# PIC32MK0512GPH064 device description
Architecture: MIPS; Family: PIC32MK; Series: PIC32MK
Registers are 32-bit, read-write, no defined reset value unless marked. A register's access mark holds for its fields unless they carry their own. Offsets are from the block's base; [hi:lo] are bit positions; {n}, {i} and the like mark numbered series; 'fields as' and 'values as' point back to an identical list.

## CAN
Instances: CAN 0x1f880000 in periph_pb5_std
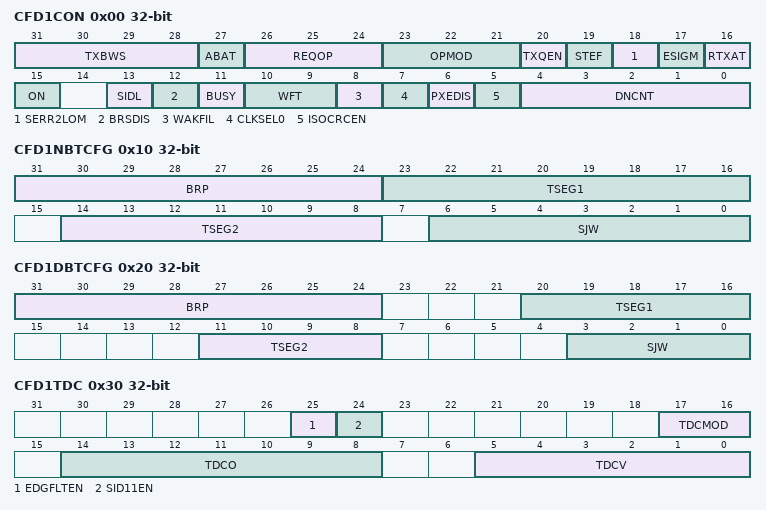
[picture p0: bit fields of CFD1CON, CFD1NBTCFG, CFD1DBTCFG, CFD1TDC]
0x00 CFD1CON — CAN Control Register
  [31:28] TXBWS — Transmit Bandwidth Sharing bits
    12=4096; 11=2048; 10=1024; 9=512; 8=256; 7=128; 6=64; 5=32; 4=16; 3=8; 2=4; 1=2; 0=No delay
  [27] ABAT — Abort All Pending Transmissions bit
    1=Signal all transmit buffers to abort transmission; 0=Module will clear this bit when all transmissions aborted
  [26:24] REQOP — Request Operation Mode bits
    7=Set Restricted Operation mode; 6=Set Normal CAN 2.0 mode; error frames on CAN FD frames; 5=Set External Loopback mode; 4=Set Configuration mode; 3=Set Listen Only mode; 2=Set Internal Loopback mode; 1=Set Disable mode; 0=Set Normal CAN FD mode; supports mixing of Full CAN FD and Classic CAN 2.0 frames
  [23:21] OPMOD — Operation Mode Status bits
    7=Module is Restricted Operation mode; 6=Module is Normal CAN 2.0 mode; error frames on CAN FD frames; 5=Module is in External Loopback mode; 4=Module is in Configuration mode; 3=Module is in Listen Only mode; 2=Module is in Internal Loopback mode; 1=Module is in Disable mode; 0=Module is in Normal CAN FD mode; supports mixing of Full CAN FD and Classic CAN 2.0 frames
  [20] TXQEN — Enable Transmit Queue bit
    1=Enables Transmit Queue and reserves space in RAM; 0=Dont reserve space in RAM for Transmit Queue
  [19] STEF — Store in Transmit Event FIFO bit
    1=Save transmitted messages in TEF; 0=Dont save transmitted messages in TEF
  [18] SERR2LOM — Transition to Listen Only Mode on System Error bit
    1=Transition to Listen Only Mode; 0=Transition to Restricted Operation Mode
  [17] ESIGM — Transmit ESI in Gateway Mode bit
    1=ESI is transmitted as recessive when ESI of message is high or CAN controller error passive; 0=ESI reflects error status of CAN controller
  [16] RTXAT — Restrict Retransmission Attempts bit
    1=Restricted retransmission attempts; 0=Unlimited number of retransmission attempts
  [15] ON — Enable bit
    1=CAN module is enabled; 0=CAN module is disabled
  [13] SIDL — Stop-in-Idle Control bit
    1=Stop module operation in Idle mode; 0=Dont stop module operation in Idle mode
  [12] BRSDIS — Bit Rate Switching Disable bit
    1=Bit Rate Switching is Disabled; 0=Bit Rate Switching depends on BRS in the Transmit Message Object
  [11] BUSY — CAN Module is Busy bit
    1=The CAN module is active; 0=The CAN module is inactive
  [10:9] WFT — Selectable Wake-up Filter Time bits
    3=T11FILTER (Typical 600 ns); 2=T10FILTER (Typical 375 ns); 1=T01FILTER (Typical 187 ns); 0=T00FILTER (Typical 100 ns)
  [8] WAKFIL — Enable CAN Bus Line Wake-up Filter bit
    1=Use CAN bus line filter for wake-up; 0=CAN bus line filter is not used for wake-up
  [7] CLKSEL0 — Module Clock Source Select bit
    1=REFCLK4 is active when the CAN FD module is enabled; 0=SYSCLK is active when the CAN FD module is enabled
  [6] PXEDIS — Protocol Exception Event Detection Disabled bit
    1=Protocol Exception is treated as a Form Error; 0=If a Protocol Exception is detected
  [5] ISOCRCEN — Enable ISO CRC in CAN FD Frames bit
    1=Include Stuff Bit Count in CRC Field and use Non-Zero CRC Initialization Vector; 0=Do not include Stuff Bit Count in CRC Field and use CRC Initialization Vector with all zeros
  [4:0] DNCNT — Device Net Filter Bit Number bits
    11111-10011=Invalid Selection (compare with EID); 18=Compare up to data byte 0(7-0) and Byte 1(7-0) and Byte 2(6) with EID17; 17=Compare up to data byte 0(7-0) and Byte 1(7-0) and Byte 2(7) with EID(0-16); 16=Compare up to data byte 0(7-0) and data byte 1(7-0) with EID(0-15); 15=Compare up to data byte 0(7-0) and data byte 1(7-1) with EID(0-14); 14=Compare up to data byte 0(7-0) and data byte 1(7-2) with EID(0-13); 13=Compare up to data byte 0(7-0) and data byte 1(7-3) with EID(0-12); 12=Compare up to data byte 0(7-0) and data byte 1(7-4) with EID(0-11); 11=Compare up to data byte 0(7-0) and data byte 1(7-5) with EID(0-10); 10=Compare up to data byte 0(7-0) and data byte 1(7-6) with EID(0-9); 9=Compare up to data byte 0(7-0) and data byte 1(7) with EID(0-8); 8=Compare up to data byte 0(7-0) with EID(0-7); 7=Compare up to data byte 0(7-1) with EID(0-6); 6=Compare up to data byte 0(7-2) with EID(0-5); 5=Compare up to data byte 0(7-3) with EID(0-4); 4=Compare up to data byte 0(7-4) with EID(0-3); 3=Compare up to data byte 0(7-5) with EID(0-2); 2=Compare up to data byte 0(7-6) with EID(0-1); 1=Compare up to data byte 0 bit 7 with EID0; 0=Do not compare data bytes
0x10 CFD1NBTCFG — Nominal Bit Time Configuration Register
  [31:24] BRP — Baud Rate Prescaler bits
    255=Tq = 256/Fsys; 0=Tq = 1/Fsys
  [23:16] TSEG1 — Time Segment 1 bits
    255=Length is 256 x Tq; 0=Length is 1 x Tq
  [14:8] TSEG2 — Time Segment 2 bits
    31=Length is 128 x Tq; 0=Length is 1 x Tq
  [6:0] SJW — Synchronization Jump Width bits
    127=Length is 128 x Tq; 0=Length is 1 x Tq
0x20 CFD1DBTCFG — Data Bit Time Configuration Register
  [31:24] BRP — Baud Rate Prescaler bits
    255=Tq is 256/Fsys; 0=Tq is 1/Fsys
  [20:16] TSEG1 — Time Segment 1 bits
    {v}=Length is {v+1} x Tq (v=0..31)
  [11:8] TSEG2 — Time Segment 2 bits
    {v}=Length is {v+1} x Tq (v=0..15)
  [3:0] SJW — Synchronization Jump Width bits
    {v}=Length is {v+1} x Tq (v=0..15)
0x30 CFD1TDC — Transmitter Delay Compensation Register
  [25] EDGFLTEN — Enable Edge Filtering during Bus Integration state bit
    1=Edge Filtering enabled; 0=Edge Filtering disabled
  [24] SID11EN — Enable 12-Bit SID in CAN FD Base Format Messages bit
    1=RRS is used as SID11 in CAN FD base format messages: SID(11-0) = {SID(10-0); 0=Do not use RRS; SID(10-0) according to ISO11898-1 2015
  [17:16] TDCMOD — Transmitter Delay Compensation Mode bits
    2=Auto; measure delay and add CFDxDBTCFG.TSEG1; add TDCO; 1=Manual; Do not measure use TDCV plus TDCO from the register; 0=Disable
  [14:8] TDCO — Transmitter Delay Compensation Offset bits
    {v}={v} x SYSCLK (v=0..63)
  [5:0] TDCV — Transmitter Delay Compensation Value bits; Secondary Sample Point
    {v}={v} x SYSCLK (v=0..63)
0x40 CFD1TBC — CAN Time Base Counter Register
  [31:0] TBC — CAN Base Counter bits
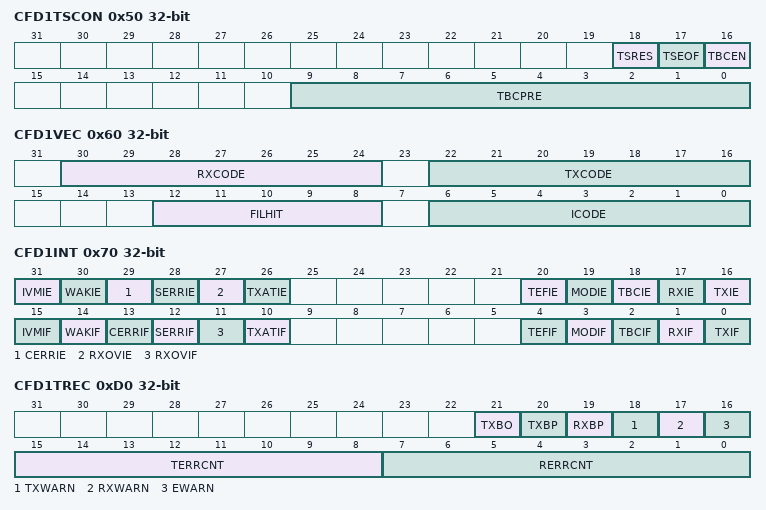
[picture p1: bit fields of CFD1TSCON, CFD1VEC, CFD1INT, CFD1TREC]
0x50 CFD1TSCON — CAN Time Stamp Control Register
  [18] TSRES — Time Stamp Resolution bit
    1=At sample point of the bit following the FDF bit; 0=At sample point of SOF
  [17] TSEOF — Time Stamp EOF bit
    1=Time Stamp when frame is taken valid (11898-1 10.7); 0=Time Stamp at beginning of Frame (classical frame) at sample point of SOF / FD frame: see the TSRES bit
  [16] TBCEN — Time Base Counter Enable bit
    1=Enable TBC; 0=Stop and reset TBC
  [9:0] TBCPRE — CAN Time Base Counter Prescaler bits
    0x1ff=TBC increments every 1024 SYSCLK clock cycles; 0=TBC increments every 1 SYSCLK clock cycle
0x60 CFD1VEC — Interrupt Code Register
  [30:24] RXCODE — Receive Interrupt Flag Code bits
    64=No interrupt; {v}=FIFO {v} Interrupt (v=1..31); 0=Reserved. FIFO 0 cant receive.
  [22:16] TXCODE — Transmit Interrupt Flag Code bits
    64=No interrupt; {v}=FIFO {v} Interrupt (v=0..31)
  [12:8] FILHIT — Filter Hit Number bits
    {v}=Filter {v} (v=0..31)
  [6:0] ICODE — Interrupt Flag Code bits
    74=Transmit attempt interrupt (any bit in the CFDxTXATIF register is set); 73=Transmit event FIFO interrupt (any bit in the CFDxTEFIF register is set); 72=Invalid message occurred (IVMIF/IE); 71=CAN module mode change Occurred (MODIF/IE); 70=CAN Timer Overflow (CTMRIF/IE); 69=RX/TX MAB overflow/underflow (RX: message received before previous message was saved to memory; TX: cannot feed TX MAB fast enough to transmit consistent data.) (SERRIF/IE); 68=Address error interrupt (illegal FIFO address presented to system) (SERRIF/IE); 67=Receive FIFO overflow interrupt (any bit in CFDxRXOVIF set); 66=Wake-up interrupt (WAKIF/WAKIE); 65=Error interrupt (CERRIF/IE); 64=No interrupt; {v}=FIFO {v} interrupt (TFIF{v} or RFIF{v} set) (v=1..31); 0=FIFO 0 interrupt (TFIF0 set)
0x70 CFD1INT — Interrupt Register
  [31] IVMIE — Invalid Message Interrupt Enable bit
    1=Interrupts are enabled; 0=Interrupts are disabled
  [30] WAKIE — Bus Wake Up Activity Interrupt Enable bit
    1=Interrupts are enabled; 0=Interrupts are disabled
  [29] CERRIE — CAN Bus Error Interrupt Enable bit
    1=Interrupts are enabled; 0=Interrupts are disabled
  [28] SERRIE — System Error Interrupt Enable bit
    1=Interrupts are enabled; 0=Interrupts are disabled
  [27] RXOVIE — Receive Buffer Overflow Interrupt Enable bit
    1=Interrupts are enabled; 0=Interrupts are disabled
  [26] TXATIE — Transmit Attempt Interrupt Enable bit
    1=Interrupts are enabled; 0=Interrupts are disabled
  [20] TEFIE — Transmit Event FIFO Interrupt Enable bit
    1=Interrupts are enabled
  [19] MODIE — Mode Change Interrupt Enable bit
    1=Interrupts are enabled; 0=Interrupts are disabled
  [18] TBCIE — CAN Timer Interrupt Enable bit
    1=Interrupts are enabled; 0=Interrupts are disabled
  [17] RXIE — Receive Object Interrupt Enable bit
    1=Interrupts are enabled; 0=Interrupts are disabled
  [16] TXIE — Transmit Object Interrupt Enable bit
    1=Interrupts are enabled; 0=Interrupts are disabled
  [15] IVMIF — Invalid Message Interrupt Flag bit
    1=An invalid message interrupt is pending; 0=No invalid message interrupts are pending
  [14] WAKIF — Bus Wake Up Activity Interrupt Flag bit
    1=A wake-up interrupt is pending; 0=No wake-up interrupts are pending
  [13] CERRIF — CAN Bus Error Interrupt Flag bit
    1=A CAN bus error interrupt is pending; 0=No CAN bus error interrupts are pending
  [12] SERRIF — System Error Interrupt Flag bit
    1=A system error occurred (collision on dual-port RAM); 0=No system error occurred
  [11] RXOVIF — Receive Object Overflow Interrupt Flag bit
    1=Receive object overflow occurred; 0=No receive object overflow has occurred
  [10] TXATIF — Transmit Attempt Interrupt Flag bit
    1=A transmit interrupt is pending in one or more of the designated 32 FIFOs denoted by which of the 32 bits in the CFDxTXATIF register are set; 0=No transmit FIFO interrupts are pending
  [4] TEFIF — Transmit Event FIFO Interrupt Flag bit
    1=Receive buffer overflow occurred; 0=No receive buffer overflow has occurred
  [3] MODIF — CAN Mode Change Interrupt Flag bit
    1=CAN module mode change occurred (OPMOD has changed to reflect the REQOP bits); 0=No mode change occurred
  [2] TBCIF — CAN Timer Overflow Interrupt Flag bit
    1=TBC has overflowed; 0=TBC did not overflow
  [1] RXIF — Receive Object Interrupt Flag bit
    1=Receive object interrupt pending; 0=No receive object interrupts pending
  [0] TXIF — Transmit Object Interrupt Flag bit
    1=Transmit object interrupt pending; 0=No transmit object interrupts pending
0x80 CFD1RXIF — Receive Interrupt Status Register
  [31:1] RFIF — Receive FIFO Interrupt Pending bits
    1=One or more enabled receive FIFO interrupts are pending; 0=No enabled receive FIFO interrupts are pending
0x90 CFD1TXIF — Transmit Interrupt Status Register
  [31:0] TFIF — Transmit FIFO/Transmit Queue Interrupt Pending bits
    1=One or more enabled transmit FIFO/Transmit Queue interrupts are pending; 0=No enabled transmit FIFO/Transmit Queue interrupt are pending
0xA0 CFD1RXOVIF — Receive Overflow Interrupt Status Register
  [31:1] RFOVIF — Receive FIFO Overflow Interrupt Pending bits
    1=Interrupt is pending; 0=Interrupt not pending
0xB0 CFD1TXATIF — Transmit Attempt Interrupt Status Register
  [31:0] TFATIF — Transmit FIFO/Transmit Queue Attempt Interrupt Pending bits
    values as CFD1INT.TXATIF
0xC0 CFD1TXREQ — Transmit Request Register
  [31:0] TXREQ — Message Send Request bits
0xD0 CFD1TREC ro — Transmit/Receive Error Count Register
  [21] TXBO — Transmitter in Error State Bus Off bit (TERRCNT greater than 255)
    1=Indicates that the number of transmit errors is greater than 255; 0=Indicates that transmit errors are less than 255
  [20] TXBP — Transmitter in Error State Bus Passive bit (TERRCNT greater than 127)
    1=Indicates that the number of transmit errors is greater than 127; 0=Indicates that transmit errors are less than or equal to 127
  [19] RXBP — Receiver in Error State Bus Passive bit (RERRCNT greater than 127)
    1=Indicates that the number of receive errors is greater than 127; 0=Indicates that transmit errors are less than or equal to 127
  [18] TXWARN — Transmitter in Error State Warning bit (128 greater than TERRCNT greater than 95)
    1=Indicates that the number of transmit errors are less than 128; 0=Indicates that transmit errors are greater than or equal to 95
  [17] RXWARN — Receiver in Error State Warning bit (128 greater than RERRCNT greater than 95)
    1=Indicates that the number of receives errors is less than 128; 0=Indicates that receive errors are greater than or equal to 95
  [16] EWARN — Transmitter or Receiver is in Error State Warning bit
    1=TXWARN or RXWARN is set; 0=No transmit or receive warnings
  [15:8] TERRCNT — Transmit Error Counter bits
    255=Greater than or equal to 255 Transmit errors; 254=254 Transmit errors; 1=1 transmit error; 0=No transmit errors
  [7:0] RERRCNT — Receive Error Counter bits
    255=Greater than or equal to 255 Receive errors; 254=254 receive errors; 1=1 receive error; 0=No receive errors
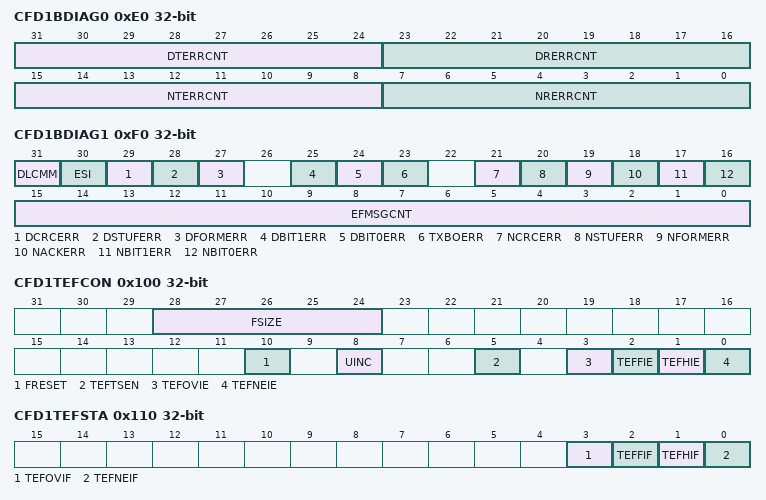
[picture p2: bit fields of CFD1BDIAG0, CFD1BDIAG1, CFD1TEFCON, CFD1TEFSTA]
0xE0 CFD1BDIAG0 — Bus Diagnostics Register 0
  [31:24] DTERRCNT — Data Bit Rate Transmit Error Counter bits
  [23:16] DRERRCNT — Data Bit Rate Receive Error Counter bits
  [15:8] NTERRCNT — Nominal Bit Rate Transmit Error Counter bits
  [7:0] NRERRCNT — Nominal Bit Rate Receive Error Counter bits
0xF0 CFD1BDIAG1 — Bus Diagnostics Register
  [31] DLCMM — Data Length Code (DLC) Mismatch Status bit
    1=Payload size error. During a transmission or reception the Data Length Code exceeds the payload size of the FIFO element defined in the PLSIZE bits (CFDxFIFOCONn).; 0=No payload size error occurred
  [30] ESI — Error State Indicator (ESI) Flag Status bit
    1=ESI flag of a received CAN FD message was set; 0=ESI flag of a received CAN FD message was not set
  [29] DCRCERR — Data CRC Error Status bit
    1=CRC checksum of a received message was incorrect. The CRC of an incoming message does not match with the CRC calculated from the received data; 0=No received message data CRC error occurred
  [28] DSTUFERR — Data Stuffing Error Status bit
    1=More than five equal bits in a sequence have occurred in a portion of a received message where this is not allowed; 0=No data received message errors
  [27] DFORMERR — Data Format Error Status bit
    1=Data fixed format portion of a received frame has the wrong format; 0=No format errors occurred
  [25] DBIT1ERR — Data Bit Logical 1 Error Status bit
    1=During the data transmission of a message (with the exception of the arbitration field); 0=No data logical 1 bit transmission error occurred
  [24] DBIT0ERR — Data Bit Logical 0 Error Status bit
    1=During the data transmission of a message the monitored bus value was recessive. During Bus Off recovery, this status is set each time a sequence of 11 recessive bits has been monitored.; 0=No data logical 0 bit transmission error occurred
  [23] TXBOERR — Transmit Bus Off Error Status bit
    1=Transmit error occurred and device enter Bus Off mode and automatically recovered; 0=No transmit Bus Off error occurred
  [21] NCRCERR — Nominal CRC Error Status bit
    1=The CRC checksum of a nominal received message was incorrect; 0=No nominal CRC received message error occurred
  [20] NSTUFERR — Nominal Stuffing Error Status bit
    1=More than five equal bits in a sequence have occurred in a part of a nominal received message where this is not allowed; 0=No nominal bit stuffing errors have occurred
  [19] NFORMERR — Nominal Format Error Status bit
    1=A fixed format portion of a nominal received frame has the wrong format; 0=No nominal format error occurred
  [18] NACKERR — Not Acknowledged Error Status bit
    1=A transmitted message was not acknowledged; 0=A transmitted message was acknowledged
  [17] NBIT1ERR — Nominal Bit Logical 1 Error Status bit
    1=During the transmission of a nominal message (with the exception of the arbitration field); 0=No nominal bit logical 1 error occurred
  [16] NBIT0ERR — Nominal Bit Logical 0 Error Status bit
    1=During the transmission of a nominal message; 0=No nominal bit logical 0 error occurred
  [15:0] EFMSGCNT — Error Free Message Counter Status bits
    0xffff=65536 error free messages since the last register read; 0=0 error free messages since the last register read
0x100 CFD1TEFCON — Transmit Event FIFO Control Register
  [28:24] FSIZE — FIFO Size bits
    {v}=FIFO is {v+1} messages deep (v=1..31); 0=FIFO is 1 message deep
  [10] FRESET — FIFO Reset bit
    1=FIFO will be reset when bit is set; 0=No effect
  [8] UINC — Increment Tail bit
  [5] TEFTSEN — Transmit Event FIFO Time Stamp Enable bit
    1=Time stamp elements in TEF; 0=Do not time stamp elements in TEF
  [3] TEFOVIE — Transmit Event FIFO Overflow Interrupt Enable bit
    1=Interrupt enabled for overflow event; 0=Interrupt disabled for overflow event
  [2] TEFFIE — Transmit Event FIFO Full Interrupt Enable bit
    1=Interrupt enabled for FIFO full; 0=Interrupt disabled for FIFO full
  [1] TEFHIE — Transmit Event FIFO Half Full Interrupt Enable bit
    1=Interrupt enabled for FIFO half full; 0=Interrupt disabled for FIFO half full
  [0] TEFNEIE — Transmit Event FIFO Not Empty Interrupt Enable bit
    1=Interrupt enabled for FIFO not empty; 0=Interrupt disabled for FIFO not empty
0x110 CFD1TEFSTA — Transmit Event FIFO Status Register
  [3] TEFOVIF — Transmit Event FIFO Overflow Interrupt Flag bit
    1=Overflow event has occurred; 0=No overflow event has occurred
  [2] TEFFIF — Transmit Event FIFO Full Interrupt Flag bit
    1=FIFO is full; 0=FIFO is not full
  [1] TEFHIF — Transmit Event FIFO Half Full Interrupt Flag bit
    1=FIFO is greater than or equal to half full; 0=FIFO is less than half full
  [0] TEFNEIF — Transmit Event FIFO Not Empty Interrupt Flag bit
    1=FIFO is not empty (has at least one message); 0=FIFO is empty
0x120 CFD1TEFUA — Transmit Event FIFO User Address Register
  [31:0] TEFUA — Transmit Event FIFO User Address bits
0x130 CFD1FIFOBA — Message Memory Base Address Register
  [31:0] FIFOBA — Message Memory Base Address bits
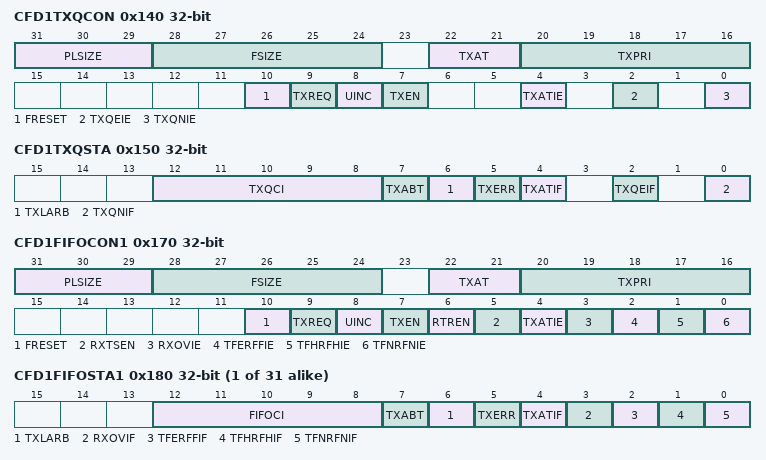
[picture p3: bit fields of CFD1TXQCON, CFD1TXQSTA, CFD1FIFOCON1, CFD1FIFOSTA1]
0x140 CFD1TXQCON — Transmit Queue Control Register
  [31:29] PLSIZE — Payload Size bits
    7=64 data bytes; 6=48 data bytes; 5=32 data bytes; 4=24 data bytes; 3=20 data bytes; 2=16 data bytes; 1=12 data bytes; 0=8 data bytes
  [28:24] FSIZE — FIFO Size bits
    {v}=FIFO is {v+1} Messages deep (v=1..31); 0=FIFO is 1 Message deep
  [22:21] TXAT — Retransmission Attempts bits
    2=Unlimited number of retransmission attempts; 1=Three retransmission attempts; 0=Disable retransmission attempts
  [20:16] TXPRI — Message Transmit Priority bits
    31=Highest Message Priority; {v}=Message priority {v} (v=1..30); 0=Lowest Message Priority
  [10] FRESET — FIFO Reset bit
    1=FIFO will be reset when bit is set; cleared by hardware when FIFO is reset. The user application should poll whether this bit is clear before taking any action.; 0=No effect
  [9] TXREQ — Message Send Request bit
    1=Requests sending a message; the bit will automatically clear when all the messages queued in the Transmit Queue are successfully sent; 0=Clearing the bit to 0 while set will request a message abort
  [8] UINC — Increment Head/Tail bit
    1=FIFO head will increment by a single message; 0=FIFO head will not increment by a single message
  [7] TXEN — TX Enable
    1=Transmit Message Queue. This bit always reads as 1.
  [4] TXATIE — Transmit Attempts Exhausted Interrupt Enable bit
    1=Enable interrupt; 0=Disable interrupt
  [2] TXQEIE — Transmit Queue Empty Interrupt Enable bit
    1=Interrupt enabled for Transmit Queue empty; 0=Interrupt disabled for Transmit Queue empty
  [0] TXQNIE — Transmit Queue Not Full Interrupt Enable bit
    1=Interrupt enabled for Transmit Queue not full; 0=Interrupt disabled for Transmit Queue not full
0x150 CFD1TXQSTA — Transmit Queue Status Register
  [12:8] TXQCI — Transmit Queue Message Index bits
  [7] TXABT — Message Aborted Status bit
    1=Message was aborted; 0=Message completed successfully
  [6] TXLARB — Message Lost Arbitration Status bit
    1=Message lost arbitration while being sent; 0=Message did not loose arbitration while being sent
  [5] TXERR — Error Detected During Transmission bit
    1=A bus error occurred while the message was being sent; 0=A bus error did not occur while the message was being sent
  [4] TXATIF — Transmit Attempts Exhausted Interrupt Pending bit
    1=Interrupt pending; 0=Interrupt Not pending
  [2] TXQEIF — Transmit Queue Empty Interrupt Flag bit
    1=Transmit Queue is empty; 0=Transmit Queue is not empty
  [0] TXQNIF — Transmit Queue Not Full Interrupt Flag bit
    1=Transmit Queue is not full; 0=Transmit Queue is full
0x160 CFD1TXQUA — Transmit Queue User Address Register
  [31:0] TXQUA — Transmit Queue User Address bits
0x170 CFD1FIFOCON1 — FIFO Control Registe
  [31:29] PLSIZE — Payload Size bits
    values as CFD1TXQCON.PLSIZE
  [28:24] FSIZE — FIFO Size bits
    values as CFD1TXQCON.FSIZE
  [22:21] TXAT — Retransmission Attempts bits
    values as CFD1TXQCON.TXAT
  [20:16] TXPRI — Message Transmit Priority bits (EXPANDED)
    values as CFD1TXQCON.TXPRI
  [10] FRESET — FIFO Reset bit
    1=FIFO will be reset when bit is set; cleared by hardware when FIFO is reset. User should poll whether this bit is clear before taking any action; 0=No effect
  [9] TXREQ — Message Send Request bit
    1=(TXEN is 1) Requests sending a message; the bit will automatically clear when all the messages queued in the FIFO are successfully sent / (TXEN is 0) This bit has no effect; 0=(TXEN is 1) Clearing the bit to 0 while set will request a message abort. / (TXEN is 0) This bit has no effect.
  [8] UINC — Increment Head / Tail bit
    1=(TXEN is 1) The FIFO head will increment by a single message / (TXEN is 0) The FIFO tail will increment by a single message; 0=(TXEN is 1) The FIFO head will not increment by a single message / (TXEN is 0) The FIFO tail will not increment by a single message
  [7] TXEN — TX / RX Buffer Selection bit
    1=Transmit Message Object; 0=Receive Message Object
  [6] RTREN — Auto RTR Enable bit
    1=When a remote transmit is received; 0=When a remote transmit is received
  [5] RXTSEN — Received Message Time Stamp Enable bit
    1=Capture time stamp in received message object in RAM; 0=Dont capture time stamp
  [4] TXATIE — Transmit Attempts Exhausted Interrupt Enable bit
    1=Enable interrupt; 0=Disable interrupt
  [3] RXOVIE — Overflow Interrupt Enable bit
    values as CFD1TEFCON.TEFOVIE
  [2] TFERFFIE — Transmit/Receive FIFO Empty/Full Interrupt Enable bit
    1=(TXEN is 1) Interrupt enabled for FIFO empty / (TXEN is 0) Interrupt enabled for FIFO full; 0=(TXEN is 1) Interrupt disabled for FIFO empty / (TXEN is 0) Interrupt disabled for FIFO full
  [1] TFHRFHIE — Transmit/Receive FIFO Half Empty/Half Full Interrupt Enable bit
    1=(TXEN is 1) Interrupt enabled for FIFO half empty / (TXEN is 0) Interrupt enabled for FIFO half full; 0=(TXEN is 1) Interrupt disabled for FIFO half empty / (TXEN is 0) Interrupt disabled for FIFO half full
  [0] TFNRFNIE — Transmit/Receive FIFO Not Full/Not Empty Interrupt Enable bit
    1=(TXEN is 1) Interrupt enabled for FIFO not full / (TXEN is 0) Interrupt enabled for FIFO not empty; 0=(TXEN is 1) Interrupt disabled for FIFO not full / (TXEN is 0) Interrupt disabled for FIFO not empty
{0x150+0x30*i} CFD1FIFOSTA{i} (i=1..31)
  [12:8] FIFOCI, [7] TXABT, [6] TXLARB, [5] TXERR, [4] TXATIF, [3] RXOVIF, [2] TFERFFIF, [1] TFHRFHIF, [0] TFNRFNIF
{0x160+0x30*i} CFD1FIFOUA{i} (i=1..31)
  [31:0] FIFOUA — FIFO User Address bits
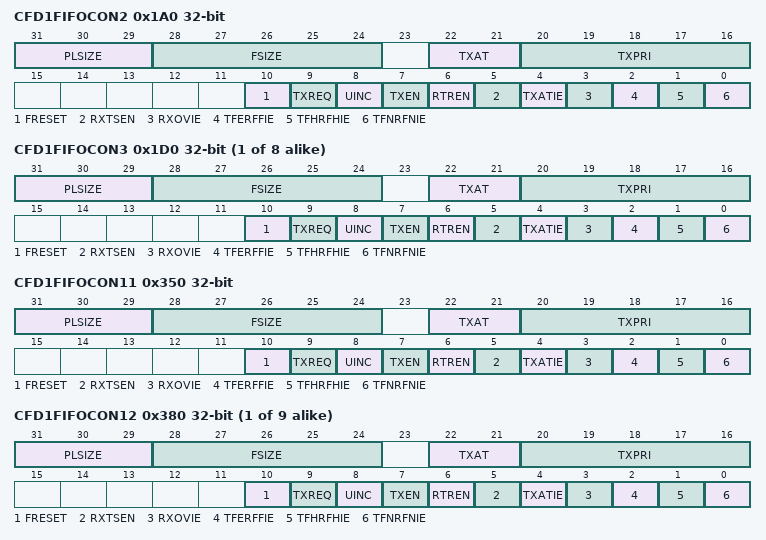
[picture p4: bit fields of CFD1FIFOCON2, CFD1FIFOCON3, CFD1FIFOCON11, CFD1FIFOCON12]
0x1A0 CFD1FIFOCON2 — FIFO Control Register
  fields as CFD1FIFOCON1
{0x140+0x30*i} CFD1FIFOCON{i} (i=3..10) — FIFO Control Register
  [31:29] PLSIZE — Payload Size bits
    values as CFD1TXQCON.PLSIZE
  [28:24] FSIZE — FIFO Size bits
    values as CFD1TXQCON.FSIZE
  [22:21] TXAT — Retransmission Attempts bits
    3=Unlimited number of retransmission attempts; 2=Unlimited number of retransmission attempts; 1=Three retransmission attempts; 0=Disable retransmission attempts
  [20:16] TXPRI — Message Transmit Priority bits (EXPANDED)
    values as CFD1TXQCON.TXPRI
  [10] FRESET — FIFO Reset bit
    values as CFD1FIFOCON1.FRESET
  [9] TXREQ — Message Send Request bit
    values as CFD1FIFOCON1.TXREQ
  [8] UINC — Increment Head / Tail bit
    values as CFD1FIFOCON1.UINC
  [7] TXEN — TX / RX Buffer Selection bit
    1=Transmit Message Object; 0=Receive Message Object
  [6] RTREN — Auto RTR Enable bit
    values as CFD1FIFOCON1.RTREN
  [5] RXTSEN — Received Message Time Stamp Enable bit
    values as CFD1FIFOCON1.RXTSEN
  [4] TXATIE — Transmit Attempts Exhausted Interrupt Enable bit
    1=Enable interrupt; 0=Disable interrupt
  [3] RXOVIE — Overflow Interrupt Enable bit
    values as CFD1TEFCON.TEFOVIE
  [2] TFERFFIE — Transmit/Receive FIFO Empty/Full Interrupt Enable bit
    values as CFD1FIFOCON1.TFERFFIE
  [1] TFHRFHIE — Transmit/Receive FIFO Half Empty/Half Full Interrupt Enable bit
    values as CFD1FIFOCON1.TFHRFHIE
  [0] TFNRFNIE — Transmit/Receive FIFO Not Full/Not Empty Interrupt Enable bit
    values as CFD1FIFOCON1.TFNRFNIE
0x350 CFD1FIFOCON11 — FIFO Control Registe
  fields as CFD1FIFOCON3
{0x140+0x30*i} CFD1FIFOCON{i} (i=12..20) — FIFO Control Register
  fields as CFD1FIFOCON3
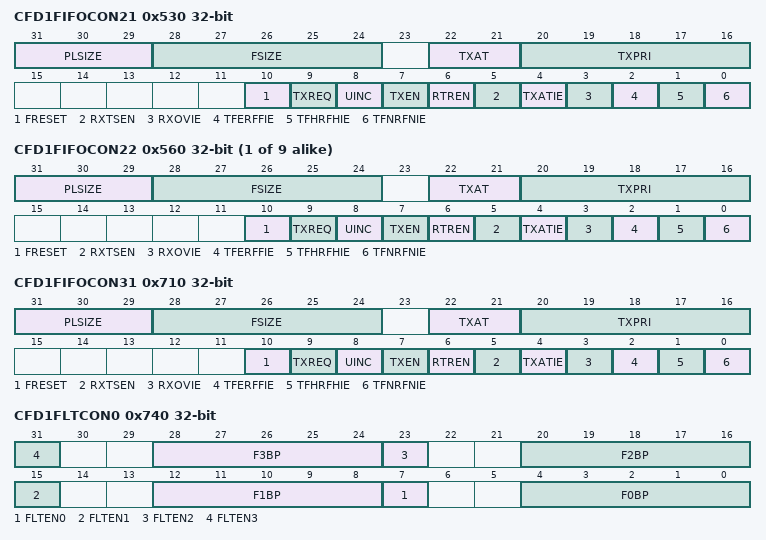
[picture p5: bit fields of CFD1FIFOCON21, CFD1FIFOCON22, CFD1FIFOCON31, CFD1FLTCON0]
0x530 CFD1FIFOCON21 — FIFO Control Registe
  fields as CFD1FIFOCON3
{0x140+0x30*i} CFD1FIFOCON{i} (i=22..30) — FIFO Control Register
  fields as CFD1FIFOCON3
0x710 CFD1FIFOCON31 — FIFO Control Registe
  fields as CFD1FIFOCON3
0x740 CFD1FLTCON0 — Filter Control Register
  [8n+7] FLTEN{n} (n=0..3) — Enable Filter n to Accept Messages bits
    1=Filter is enabled; 0=Filter is disabled
  [28:24] F3BP — Pointer to Object when Filter n hits bits
    {v}=Message matching filter is stored in Object {v} (v=1..31); 0=Reserved. Object 0 is the TX Queue and cannot receive messages.
  [20:16] F2BP — Pointer to Object when Filter n hits bits
    values as F3BP
  [12:8] F1BP — Pointer to Object when Filter n hits bits
    values as F3BP
  [4:0] F0BP — Pointer to Object when Filter n hits bits
    {v}=Message matching filter is stored in Object {v} (v=1..31); 0=Reserved. Object 0 is the RX Queue and cannot receive messages.
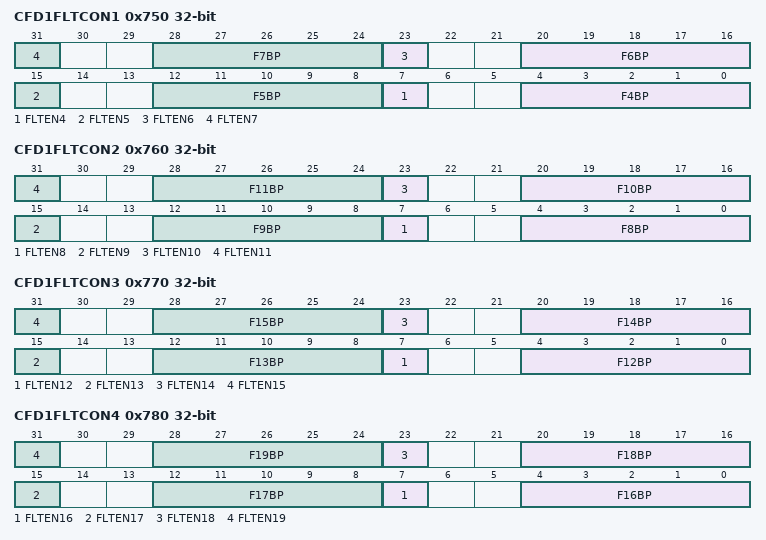
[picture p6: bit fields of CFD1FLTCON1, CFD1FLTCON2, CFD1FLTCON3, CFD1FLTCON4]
0x750 CFD1FLTCON1 — Filter Control Registe
  [8n-25] FLTEN{n} (n=4..7) — Enable Filter n to Accept Messages bits
    1=Filter is enabled; 0=Filter is disabled
  [8n-28:8n-32] F{n}BP (n=4..7) — Pointer to Object when Filter n hits bits
    values as CFD1FLTCON0.F3BP
0x760 CFD1FLTCON2 — Filter Control Register
  [8n-57] FLTEN{n} (n=8..11) — Enable Filter n to Accept Messages bits
    1=Filter is enabled; 0=Filter is disabled
  [8n-60:8n-64] F{n}BP (n=8..11) — Pointer to Object when Filter n hits bits
    values as CFD1FLTCON0.F3BP
0x770 CFD1FLTCON3 — Filter Control Register
  [8n-89] FLTEN{n} (n=12..15) — Enable Filter n to Accept Messages bits
    1=Filter is enabled; 0=Filter is disabled
  [8n-92:8n-96] F{n}BP (n=12..15) — Pointer to Object when Filter n hits bits
    values as CFD1FLTCON0.F3BP
0x780 CFD1FLTCON4 — Filter Control Register
  [8n-121] FLTEN{n} (n=16..19) — Enable Filter n to Accept Messages bits
    1=Filter is enabled; 0=Filter is disabled
  [8n-124:8n-128] F{n}BP (n=16..19) — Pointer to Object when Filter n hits bits
    values as CFD1FLTCON0.F3BP
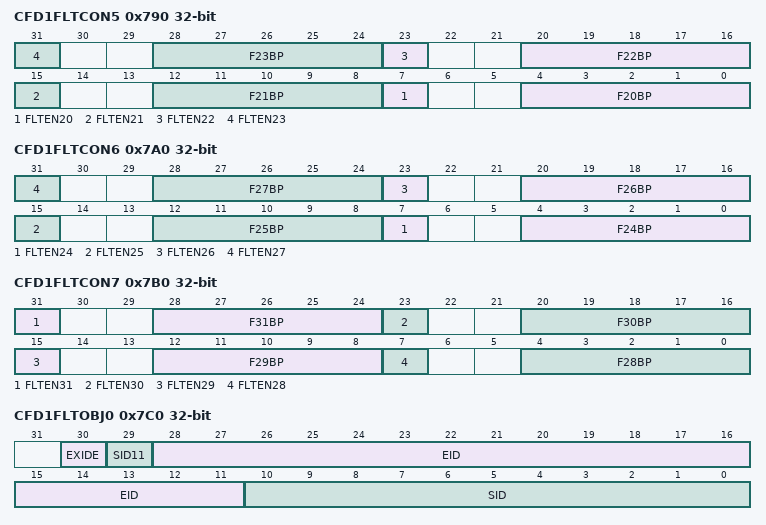
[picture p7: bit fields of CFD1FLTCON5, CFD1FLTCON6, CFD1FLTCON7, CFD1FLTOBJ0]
0x790 CFD1FLTCON5 — Filter Control Register
  [8n-153] FLTEN{n} (n=20..23) — Enable Filter n to Accept Messages bits
    1=Filter is enabled; 0=Filter is disabled
  [8n-156:8n-160] F{n}BP (n=20..23) — Pointer to Object when Filter n hits bits
    values as CFD1FLTCON0.F3BP
0x7A0 CFD1FLTCON6 — Filter Control Register
  [8n-185] FLTEN{n} (n=24..27) — Enable Filter n to Accept Messages bits
    1=Filter is enabled; 0=Filter is disabled
  [8n-188:8n-192] F{n}BP (n=24..27) — Pointer to Object when Filter n hits bits
    values as CFD1FLTCON0.F3BP
0x7B0 CFD1FLTCON7 — Filter Control Register
  [31] FLTEN31 — Enable Filter n to Accept Messages bits
    1=Filter is enabled; 0=Filter is disabled
  [8n-220:8n-224] F{n}BP (n=28..31) — Pointer to Object when Filter n hits bits
    values as CFD1FLTCON0.F3BP
  [23] FLTEN30 — Enable Filter nto Accept Messages bits
    1=Filter is enabled; 0=Filter is disabled
  [15] FLTEN29 — Enable Filter n to Accept Messages bits
    1=Filter is enabled; 0=Filter is disabled
  [7] FLTEN28 — Enable Filter n to Accept Messages bits
    1=Filter is enabled; 0=Filter is disabled
0x7C0 CFD1FLTOBJ0
  [30] EXIDE — Extended Identifier Enable bit
    1=(If MIDE is 1) Match only messages with extended identifier addresses; 0=(If MIDE is 1) Match only messages with standard identifier addresses
  [29] SID11 — Standard Identifier Filter bit
    1=Extended standard identifier to 12-bit; 0=Do not use extended standard Identifier bits
  [28:11] EID
  [10:0] SID
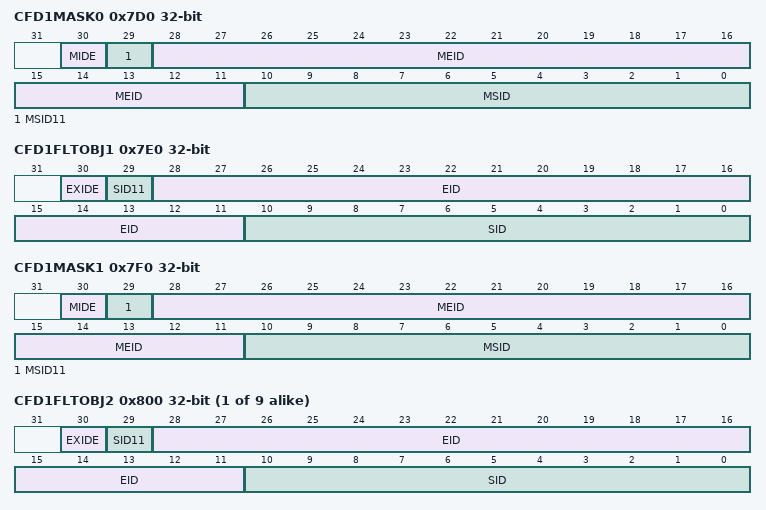
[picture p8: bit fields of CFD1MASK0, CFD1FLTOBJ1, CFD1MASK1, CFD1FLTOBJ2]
0x7D0 CFD1MASK0
  [30] MIDE — Identifier Receive Mode bit
    1=Match only message types (standard or extended address) that correspond to EXIDE bit in filter; 0=Match either standard or extended address message if filters match (i.e
  [29] MSID11 — Standard Identifier Mask bit
    1=Enable extended standard identifier mask to 12 bits (MSID; 0=Do not enable extended standard identifier mask (MSID)
  [28:11] MEID
  [10:0] MSID
0x7E0 CFD1FLTOBJ1 — Filter Object Registe
  [30] EXIDE — Extended Identifier Enable bit
    values as CFD1FLTOBJ0.EXIDE
  [29] SID11 — Standard Identifier Filter bit
    1=Extended standard identifier to 12-bit (i.e; 0=Do not use extended standard Identifier bits
  [28:11] EID
  [10:0] SID
0x7F0 CFD1MASK1 — Filter Object Registe
  fields as CFD1MASK0
{0x7C0+0x20*i} CFD1FLTOBJ{i} (i=2..10) — Filter Object Register
  fields as CFD1FLTOBJ1
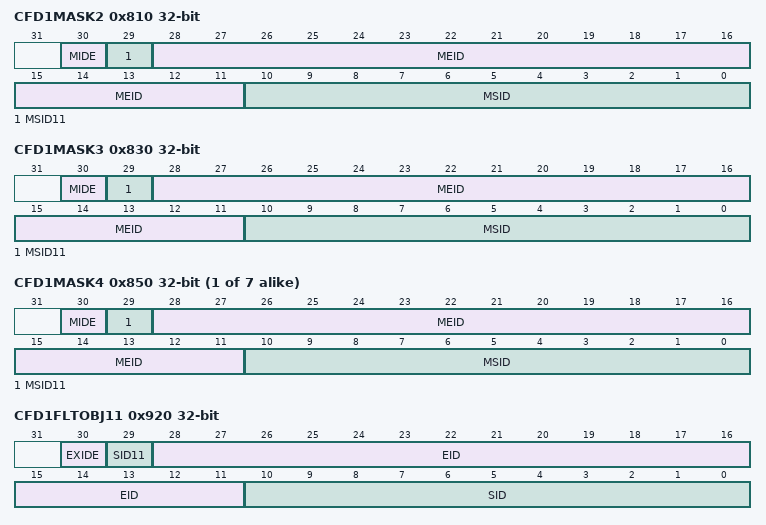
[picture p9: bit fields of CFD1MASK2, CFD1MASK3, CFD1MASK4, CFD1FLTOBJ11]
0x810 CFD1MASK2
  fields as CFD1MASK0
0x830 CFD1MASK3
  fields as CFD1MASK0
{0x7D0+0x20*i} CFD1MASK{i} (i=4..10) — Filter Object Register
  fields as CFD1MASK0
0x920 CFD1FLTOBJ11 — Filter Object Registe
  fields as CFD1FLTOBJ1
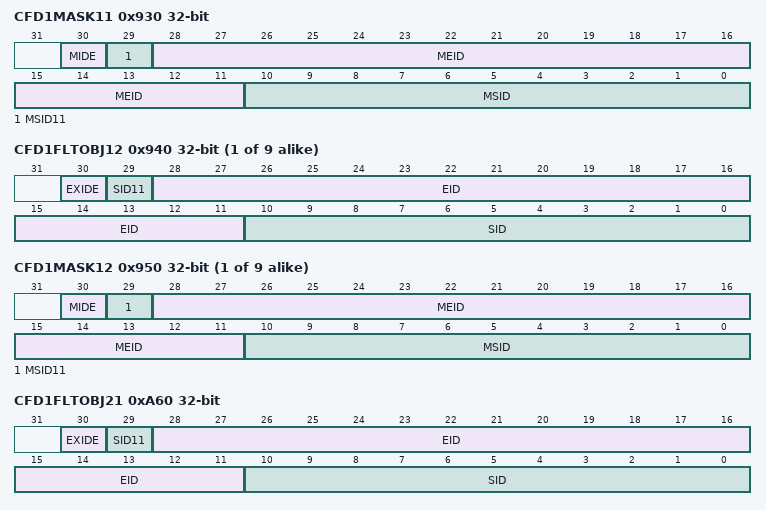
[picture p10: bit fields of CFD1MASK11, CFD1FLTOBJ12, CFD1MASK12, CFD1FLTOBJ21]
0x930 CFD1MASK11 — Filter Object Registe
  fields as CFD1MASK0
{0x7C0+0x20*i} CFD1FLTOBJ{i} (i=12..20) — Filter Object Register
  fields as CFD1FLTOBJ1
{0x7D0+0x20*i} CFD1MASK{i} (i=12..20) — Filter Object Register
  fields as CFD1MASK0
0xA60 CFD1FLTOBJ21 — Filter Object Registe
  fields as CFD1FLTOBJ1
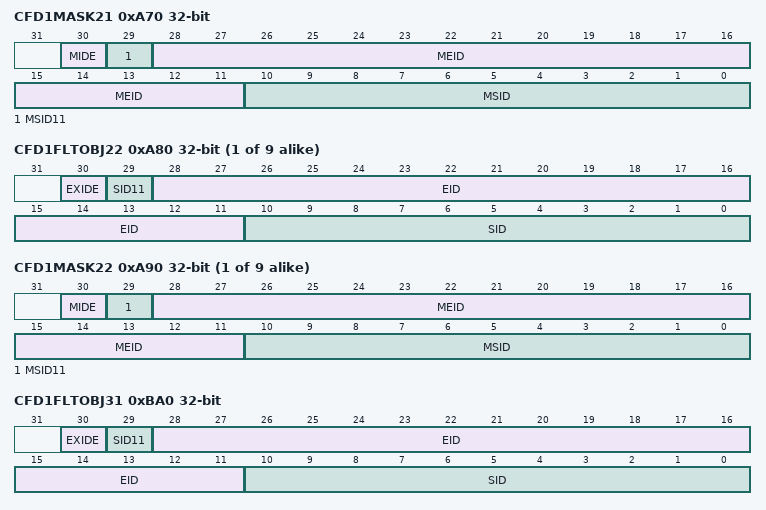
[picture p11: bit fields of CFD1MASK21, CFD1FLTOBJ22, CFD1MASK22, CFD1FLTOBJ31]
0xA70 CFD1MASK21 — Filter Object Registe
  fields as CFD1MASK0
{0x7C0+0x20*i} CFD1FLTOBJ{i} (i=22..30) — Filter Object Register
  fields as CFD1FLTOBJ1
{0x7D0+0x20*i} CFD1MASK{i} (i=22..30) — Filter Object Register
  fields as CFD1MASK0
0xBA0 CFD1FLTOBJ31 — Filter Object Registe
  fields as CFD1FLTOBJ1
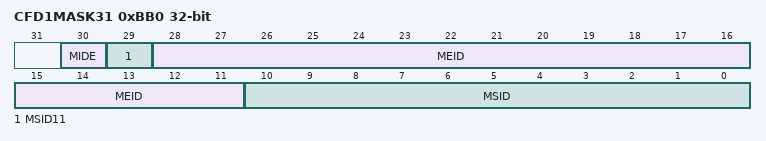
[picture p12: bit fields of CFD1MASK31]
0xBB0 CFD1MASK31 — Filter Object Registe
  fields as CFD1MASK0

## Notices in the file
Copyright (c) 2019 Microchip Technology Inc.
SPDX-License-Identifier: Apache-2.0
Licensed under the Apache License, Version 2.0 (the "License");
you may not use this file except in compliance with the License.
You may obtain a copy of the License at
http://www.apache.org/licenses/LICENSE-2.0
Unless required by applicable law or agreed to in writing, software
distributed under the License is distributed on an "AS IS" BASIS,
WITHOUT WARRANTIES OR CONDITIONS OF ANY KIND, either express or implied.
See the License for the specific language governing permissions and
limitations under the License.
